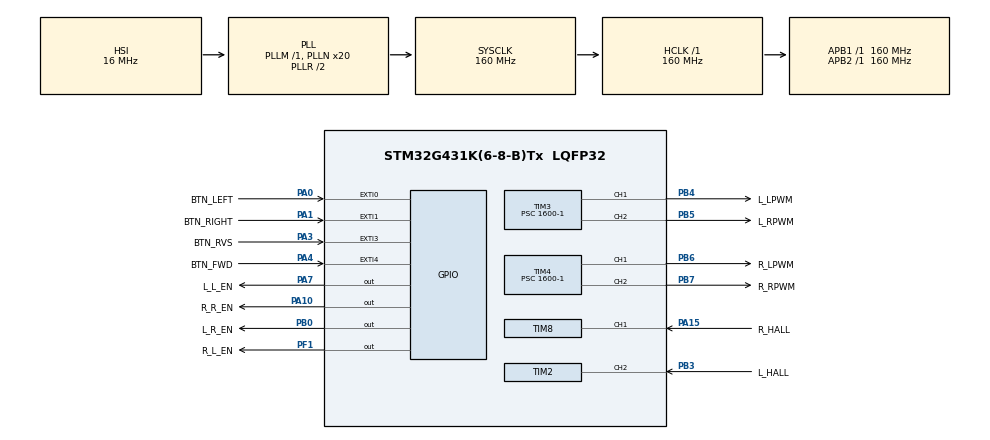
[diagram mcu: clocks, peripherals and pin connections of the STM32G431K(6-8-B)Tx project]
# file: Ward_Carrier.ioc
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Dma.Request0=TIM8_CH2
Dma.Request1=TIM2_CH1
Dma.TIM2_CH1.1.Direction=DMA_PERIPH_TO_MEMORY
Dma.TIM2_CH1.1.EventEnable=DISABLE
Dma.TIM2_CH1.1.Instance=DMA1_Channel1
Dma.TIM2_CH1.1.MemDataAlignment=DMA_MDATAALIGN_HALFWORD
Dma.TIM2_CH1.1.MemInc=DMA_MINC_ENABLE
Dma.TIM2_CH1.1.Mode=DMA_CIRCULAR
Dma.TIM2_CH1.1.PeriphDataAlignment=DMA_PDATAALIGN_WORD
Dma.TIM2_CH1.1.PeriphInc=DMA_PINC_DISABLE
Dma.TIM2_CH1.1.Polarity=HAL_DMAMUX_REQ_GEN_RISING
Dma.TIM2_CH1.1.Priority=DMA_PRIORITY_LOW
Dma.TIM2_CH1.1.RequestNumber=1
Dma.TIM2_CH1.1.SignalID=NONE
Dma.TIM2_CH1.1.SyncEnable=DISABLE
Dma.TIM2_CH1.1.SyncPolarity=HAL_DMAMUX_SYNC_NO_EVENT
Dma.TIM2_CH1.1.SyncRequestNumber=1
Dma.TIM2_CH1.1.SyncSignalID=NONE
Dma.TIM8_CH2.0.Direction=DMA_PERIPH_TO_MEMORY
Dma.TIM8_CH2.0.EventEnable=DISABLE
Dma.TIM8_CH2.0.Instance=DMA1_Channel5
Dma.TIM8_CH2.0.MemDataAlignment=DMA_MDATAALIGN_WORD
Dma.TIM8_CH2.0.MemInc=DMA_MINC_ENABLE
Dma.TIM8_CH2.0.Mode=DMA_CIRCULAR
Dma.TIM8_CH2.0.PeriphDataAlignment=DMA_PDATAALIGN_WORD
Dma.TIM8_CH2.0.PeriphInc=DMA_PINC_DISABLE
Dma.TIM8_CH2.0.Polarity=HAL_DMAMUX_REQ_GEN_RISING
Dma.TIM8_CH2.0.Priority=DMA_PRIORITY_LOW
Dma.TIM8_CH2.0.RequestNumber=1
Dma.TIM8_CH2.0.SignalID=NONE
Dma.TIM8_CH2.0.SyncEnable=DISABLE
Dma.TIM8_CH2.0.SyncPolarity=HAL_DMAMUX_SYNC_NO_EVENT
Dma.TIM8_CH2.0.SyncRequestNumber=1
Dma.TIM8_CH2.0.SyncSignalID=NONE
Mcu.Family=STM32G4
Mcu.Name=STM32G431K(6-8-B)Tx
Mcu.Package=LQFP32
NVIC.DMA1_Channel1_IRQn=true\:0\:0\:false\:false\:true\:false\:true
NVIC.DMA1_Channel5_IRQn=true\:0\:0\:false\:false\:true\:false\:true
NVIC.EXTI0_IRQn=true\:0\:0\:false\:false\:true\:true\:true
NVIC.EXTI1_IRQn=true\:0\:0\:false\:false\:true\:true\:true
NVIC.EXTI3_IRQn=true\:0\:0\:false\:false\:true\:true\:true
NVIC.EXTI4_IRQn=true\:0\:0\:false\:false\:true\:true\:true
NVIC.PriorityGroup=NVIC_PRIORITYGROUP_4
NVIC.TIM1_BRK_TIM15_IRQn=true\:0\:0\:false\:false\:true\:true\:true
NVIC.TIM3_IRQn=true\:0\:0\:false\:false\:true\:true\:true
NVIC.TIM4_IRQn=true\:0\:0\:false\:false\:true\:true\:true
NVIC.TIM7_IRQn=true\:0\:0\:false\:false\:true\:true\:true
PA0.GPIO_Label=BTN_LEFT
PA0.GPIO_ModeDefaultEXTI=GPIO_MODE_IT_RISING_FALLING
PA0.Signal=GPXTI0
PA1.GPIO_Label=BTN_RIGHT
PA1.GPIO_ModeDefaultEXTI=GPIO_MODE_IT_RISING_FALLING
PA1.Signal=GPXTI1
PA10.GPIO_Label=R_R_EN
PA10.Signal=GPIO_Output
PA11.Signal=FDCAN1_RX
PA12.Signal=FDCAN1_TX
PA13.Mode=Serial_Wire
PA13.Signal=SYS_JTMS-SWDIO
PA14.Mode=Serial_Wire
PA14.Signal=SYS_JTCK-SWCLK
PA15.GPIO_Label=R_HALL
PA15.GPIO_PuPd=GPIO_PULLUP
PA15.Signal=S_TIM8_CH1
PA3.GPIO_Label=BTN_RVS
PA3.GPIO_ModeDefaultEXTI=GPIO_MODE_IT_RISING_FALLING
PA3.Signal=GPXTI3
PA4.GPIO_Label=BTN_FWD
PA4.GPIO_ModeDefaultEXTI=GPIO_MODE_IT_RISING_FALLING
PA4.Signal=GPXTI4
PA7.GPIO_Label=L_L_EN
PA7.Signal=GPIO_Output
PA8.Signal=I2C2_SDA
PA9.Signal=I2C2_SCL
PB0.GPIO_Label=L_R_EN
PB0.Signal=GPIO_Output
PB3.GPIO_Label=L_HALL
PB3.GPIO_PuPd=GPIO_PULLUP
PB3.Signal=S_TIM2_CH2
PB4.GPIO_Label=L_LPWM
PB4.Signal=S_TIM3_CH1
PB5.GPIO_Label=L_RPWM
PB5.Signal=S_TIM3_CH2
PB6.GPIO_FM6=SYSCFG_FASTMODEPLUS_PB6
PB6.GPIO_Label=R_LPWM
PB6.Signal=S_TIM4_CH1
PB7.GPIO_FM7=SYSCFG_FASTMODEPLUS_PB7
PB7.GPIO_Label=R_RPWM
PB7.Signal=S_TIM4_CH2
PF1-OSC_OUT.GPIO_Label=R_L_EN
PF1-OSC_OUT.Signal=GPIO_Output
ProjectManager.HeapSize=0x2000
ProjectManager.StackSize=0x4000
ProjectManager.TargetToolchain=Makefile
RCC.ADC12Freq_Value=160000000
RCC.AHBFreq_Value=160000000
RCC.APB1Freq_Value=160000000
RCC.APB1TimFreq_Value=160000000
RCC.APB2Freq_Value=160000000
RCC.APB2TimFreq_Value=160000000
RCC.CortexFreq_Value=160000000
RCC.EXTERNAL_CLOCK_VALUE=12288000
RCC.HCLKFreq_Value=160000000
RCC.HSE_VALUE=8000000
RCC.HSI48_VALUE=48000000
RCC.HSI_VALUE=16000000
RCC.LSE_VALUE=32768
RCC.PLLN=20
RCC.SYSCLKFreq_VALUE=160000000
RCC.SYSCLKSource=RCC_SYSCLKSOURCE_PLLCLK
RCC.USBFreq_Value=160000000
RCC.VCOOutputFreq_Value=320000000
SH.S_TIM2_CH2.0=TIM2_CH2,TriggerSource_TI2FP2
SH.S_TIM2_CH2.1=TIM2_CH2,Input_Capture2_from_TI2
SH.S_TIM3_CH1.0=TIM3_CH1,PWM Generation1 CH1
SH.S_TIM3_CH2.0=TIM3_CH2,PWM Generation2 CH2
SH.S_TIM4_CH1.0=TIM4_CH1,PWM Generation1 CH1
SH.S_TIM4_CH2.0=TIM4_CH2,PWM Generation2 CH2
SH.S_TIM8_CH1.0=TIM8_CH1,Input_Capture1_from_TI1
SH.S_TIM8_CH1.1=TIM8_CH1,TriggerSource_TI1FP1
TIM15.AutoReloadPreload=TIM_AUTORELOAD_PRELOAD_ENABLE
TIM15.PeriodNoDither=1000
TIM15.Prescaler=160-1
TIM2.Channel-Input_Capture1_from_TI2_63=TIM_CHANNEL_1
TIM2.Channel-Input_Capture2_from_TI2=TIM_CHANNEL_2
TIM2.PeriodNoDither=65535
TIM2.Prescaler=16000-1
TIM3.AutoReloadPreload=TIM_AUTORELOAD_PRELOAD_ENABLE
TIM3.Channel-PWM\ Generation1\ CH1=TIM_CHANNEL_1
TIM3.Channel-PWM\ Generation2\ CH2=TIM_CHANNEL_2
TIM3.PeriodNoDither=200-1
TIM3.Prescaler=1600-1
TIM3.PulseNoDither_1=100-1
TIM3.PulseNoDither_2=100-1
TIM4.AutoReloadPreload=TIM_AUTORELOAD_PRELOAD_ENABLE
TIM4.Channel-PWM\ Generation1\ CH1=TIM_CHANNEL_1
TIM4.Channel-PWM\ Generation2\ CH2=TIM_CHANNEL_2
TIM4.PeriodNoDither=200-1
TIM4.Prescaler=1600-1
TIM4.PulseNoDither_1=100-1
TIM4.PulseNoDither_2=100-1
TIM6.PeriodNoDither=10000-1
TIM6.Prescaler=16000-1
TIM7.PeriodNoDither=13000-1
TIM7.Prescaler=16000-1
TIM8.Channel-Input_Capture1_from_TI1=TIM_CHANNEL_1
TIM8.Channel-Input_Capture2_from_TI1_63=TIM_CHANNEL_2
TIM8.Prescaler=16000-1
VP_SYS_VS_DBSignals.Mode=DisableDeadBatterySignals
VP_TIM15_VS_ClockSourceINT.Mode=Internal
VP_TIM2_VS_ClockSourceINT.Mode=Internal
VP_TIM2_VS_ControllerModeReset.Mode=Reset Mode
VP_TIM2_VS_indirect_ch2.Mode=Input_Capture1_from_TI2_63
VP_TIM3_VS_ClockSourceINT.Mode=Internal
VP_TIM4_VS_ClockSourceINT.Mode=Internal
VP_TIM6_VS_ClockSourceINT.Mode=Enable_Timer
VP_TIM7_VS_ClockSourceINT.Mode=Enable_Timer
VP_TIM7_VS_OPM.Mode=OPM_bit
VP_TIM8_VS_ControllerModeReset.Mode=Reset Mode
VP_TIM8_VS_indirect_ch1.Mode=Input_Capture2_from_TI1_63
board=custom

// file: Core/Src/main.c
/* USER CODE BEGIN Header */
/**
  ******************************************************************************
  * @file           : main.c
  * @brief          : Main program body
  ******************************************************************************
  * @attention
  *
  * <h2><center>&copy; Copyright (c) 2022 STMicroelectronics.
  * All rights reserved.</center></h2>
  *
  * This software component is licensed by ST under BSD 3-Clause license,
  * the "License"; You may not use this file except in compliance with the
  * License. You may obtain a copy of the License at:
  *                        opensource.org/licenses/BSD-3-Clause
  *
  ******************************************************************************
  */
/* USER CODE END Header */
#include "main.h"
#include "dma.h"
#include "tim.h"
#include "gpio.h"

void SystemClock_Config(void);
/* USER CODE BEGIN PFP */
extern void while1_in_mainCpp();
extern void initPerf();
/* USER CODE END PFP */

int main(void)
{

  /* MCU Configuration--------------------------------------------------------*/

  /* Reset of all peripherals, Initializes the Flash interface and the Systick. */
  HAL_Init();

  /* Configure the system clock */
  SystemClock_Config();

  /* Initialize all configured peripherals */
  MX_GPIO_Init();
  MX_TIM7_Init();
  MX_TIM6_Init();
  MX_TIM4_Init();
  MX_TIM3_Init();
  MX_DMA_Init();
  MX_TIM8_Init();
  MX_TIM2_Init();
  MX_TIM15_Init();
  /* USER CODE BEGIN 2 */
  initPerf();
  /* USER CODE END 2 */

  /* Infinite loop */
  while (1)
  {

    /* USER CODE BEGIN 3 */
    while1_in_mainCpp();
  }
  /* USER CODE END 3 */
}

void SystemClock_Config(void)
{
  RCC_OscInitTypeDef RCC_OscInitStruct = {0};
  RCC_ClkInitTypeDef RCC_ClkInitStruct = {0};

  /** Configure the main internal regulator output voltage
  */
  HAL_PWREx_ControlVoltageScaling(PWR_REGULATOR_VOLTAGE_SCALE1_BOOST);
  /** Initializes the RCC Oscillators according to the specified parameters
  * in the RCC_OscInitTypeDef structure.
  */
  RCC_OscInitStruct.OscillatorType = RCC_OSCILLATORTYPE_HSI;
  RCC_OscInitStruct.HSIState = RCC_HSI_ON;
  RCC_OscInitStruct.HSICalibrationValue = RCC_HSICALIBRATION_DEFAULT;
  RCC_OscInitStruct.PLL.PLLState = RCC_PLL_ON;
  RCC_OscInitStruct.PLL.PLLSource = RCC_PLLSOURCE_HSI;
  RCC_OscInitStruct.PLL.PLLM = RCC_PLLM_DIV1;
  RCC_OscInitStruct.PLL.PLLN = 20;
  RCC_OscInitStruct.PLL.PLLP = RCC_PLLP_DIV2;
  RCC_OscInitStruct.PLL.PLLQ = RCC_PLLQ_DIV2;
  RCC_OscInitStruct.PLL.PLLR = RCC_PLLR_DIV2;
  if (HAL_RCC_OscConfig(&RCC_OscInitStruct) != HAL_OK)
  {
    Error_Handler();
  }
  /** Initializes the CPU, AHB and APB buses clocks
  */
  RCC_ClkInitStruct.ClockType = RCC_CLOCKTYPE_HCLK|RCC_CLOCKTYPE_SYSCLK
                              |RCC_CLOCKTYPE_PCLK1|RCC_CLOCKTYPE_PCLK2;
  RCC_ClkInitStruct.SYSCLKSource = RCC_SYSCLKSOURCE_PLLCLK;
  RCC_ClkInitStruct.AHBCLKDivider = RCC_SYSCLK_DIV1;
  RCC_ClkInitStruct.APB1CLKDivider = RCC_HCLK_DIV1;
  RCC_ClkInitStruct.APB2CLKDivider = RCC_HCLK_DIV1;

  if (HAL_RCC_ClockConfig(&RCC_ClkInitStruct, FLASH_LATENCY_4) != HAL_OK)
  {
    Error_Handler();
  }
}

void Error_Handler(void)
{
  /* USER CODE BEGIN Error_Handler_Debug */
  /* User can add his own implementation to report the HAL error return state */
  __disable_irq();
  while (1)
  {
      while1_in_mainCpp();
  }
  /* USER CODE END Error_Handler_Debug */
}

/************************ (C) COPYRIGHT STMicroelectronics *****END OF FILE****/
